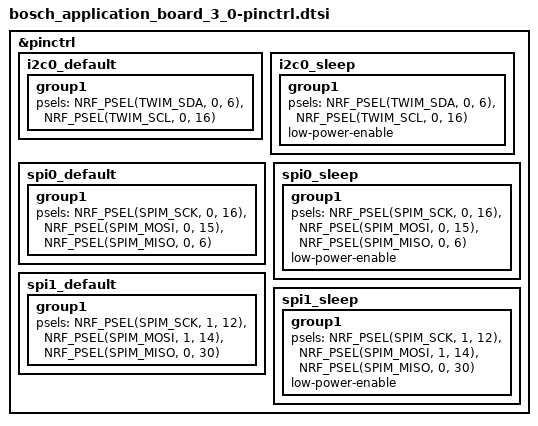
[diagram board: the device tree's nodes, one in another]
/*
 * Copyright (c) 2022 Nordic Semiconductor
 * SPDX-License-Identifier: Apache-2.0
 */

&pinctrl {

	i2c0_default: i2c0_default {
		group1 {
			psels = <NRF_PSEL(TWIM_SDA, 0, 6)>,
				<NRF_PSEL(TWIM_SCL, 0, 16)>;
		};
	};

	i2c0_sleep: i2c0_sleep {
		group1 {
			psels = <NRF_PSEL(TWIM_SDA, 0, 6)>,
				<NRF_PSEL(TWIM_SCL, 0, 16)>;
			low-power-enable;
		};
	};

	spi0_default: spi0_default {
		group1 {
			psels = <NRF_PSEL(SPIM_SCK, 0, 16)>,
				<NRF_PSEL(SPIM_MOSI, 0, 15)>,
				<NRF_PSEL(SPIM_MISO, 0, 6)>;
		};
	};

	spi0_sleep: spi0_sleep {
		group1 {
			psels = <NRF_PSEL(SPIM_SCK, 0, 16)>,
				<NRF_PSEL(SPIM_MOSI, 0, 15)>,
				<NRF_PSEL(SPIM_MISO, 0, 6)>;
			low-power-enable;
		};
	};

	spi1_default: spi1_default {
		group1 {
			psels = <NRF_PSEL(SPIM_SCK, 1, 12)>,
				<NRF_PSEL(SPIM_MOSI, 1, 14)>,
				<NRF_PSEL(SPIM_MISO, 0, 30)>;
		};
	};

	spi1_sleep: spi1_sleep {
		group1 {
			psels = <NRF_PSEL(SPIM_SCK, 1, 12)>,
				<NRF_PSEL(SPIM_MOSI, 1, 14)>,
				<NRF_PSEL(SPIM_MISO, 0, 30)>;
			low-power-enable;
		};
	};

};
